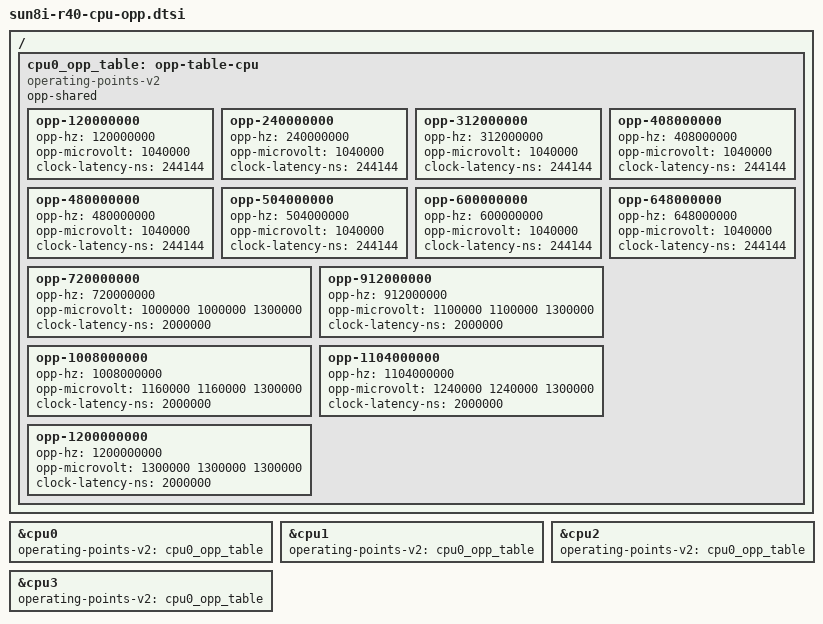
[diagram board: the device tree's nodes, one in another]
/{
	cpu0_opp_table: opp-table-cpu {
		compatible = "operating-points-v2";
		opp-shared;

		opp-120000000 {
			opp-hz = /bits/ 64 <120000000>;
			opp-microvolt = <1040000>;
			clock-latency-ns = <244144>; /* 8 32k periods */
		};

		opp-240000000 {
			opp-hz = /bits/ 64 <240000000>;
			opp-microvolt = <1040000>;
			clock-latency-ns = <244144>; /* 8 32k periods */
		};

		opp-312000000 {
			opp-hz = /bits/ 64 <312000000>;
			opp-microvolt = <1040000>;
			clock-latency-ns = <244144>; /* 8 32k periods */
		};

		opp-408000000 {
			opp-hz = /bits/ 64 <408000000>;
			opp-microvolt = <1040000>;
			clock-latency-ns = <244144>; /* 8 32k periods */
		};

		opp-480000000 {
			opp-hz = /bits/ 64 <480000000>;
			opp-microvolt = <1040000>;
			clock-latency-ns = <244144>; /* 8 32k periods */
		};

		opp-504000000 {
			opp-hz = /bits/ 64 <504000000>;
			opp-microvolt = <1040000>;
			clock-latency-ns = <244144>; /* 8 32k periods */
		};

		opp-600000000 {
			opp-hz = /bits/ 64 <600000000>;
			opp-microvolt = <1040000>;
			clock-latency-ns = <244144>; /* 8 32k periods */
		};

		opp-648000000 {
			opp-hz = /bits/ 64 <648000000>;
			opp-microvolt = <1040000>;
			clock-latency-ns = <244144>; /* 8 32k periods */
		};

		opp-720000000 {
			opp-hz = /bits/ 64 <720000000>;
			opp-microvolt = <1000000 1000000 1300000>;
			clock-latency-ns = <2000000>;
		};

		opp-912000000 {
			opp-hz = /bits/ 64 <912000000>;
			opp-microvolt = <1100000 1100000 1300000>;
			clock-latency-ns = <2000000>;
		};

		opp-1008000000 {
			opp-hz = /bits/ 64 <1008000000>;
			opp-microvolt = <1160000 1160000 1300000>;
			clock-latency-ns = <2000000>;
		};

		opp-1104000000 {
			opp-hz = /bits/ 64 <1104000000>;
			opp-microvolt = <1240000 1240000 1300000>;
			clock-latency-ns = <2000000>;
		};

		opp-1200000000 {
			opp-hz = /bits/ 64 <1200000000>;
			opp-microvolt = <1300000 1300000 1300000>;
			clock-latency-ns = <2000000>;
		};
	};
};

&cpu0 {
	operating-points-v2 = <&cpu0_opp_table>;
};

&cpu1 {
	operating-points-v2 = <&cpu0_opp_table>;
};

&cpu2 {
	operating-points-v2 = <&cpu0_opp_table>;
};

&cpu3 {
	operating-points-v2 = <&cpu0_opp_table>;
};
